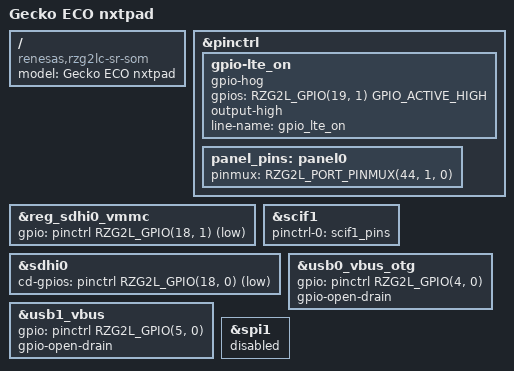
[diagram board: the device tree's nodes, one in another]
// SPDX-License-Identifier: (GPL-2.0-only OR BSD-2-Clause)
/*
 * Device Tree Source for the RZ/G2LC Solidrun SOM
 *
 * Copyright (C) 2021 Renesas Electronics Corp.
 */

#include <dt-bindings/gpio/gpio.h>
#include <dt-bindings/pinctrl/rzg2l-pinctrl.h>

/dts-v1/;
#include "rzg2lc-sr-som.dtsi"
#include "rz-hummingboard-common.dtsi"

/ {
  model = "Gecko ECO nxtpad";
  compatible = "renesas,rzg2lc-sr-som", "renesas,r9a07g044c2", "renesas,r9a07g044";
};

&pinctrl {
	/delete-node/ gpio-lte_reset;
	/delete-node/ spi1;

	gpio-lte_on {
		gpio-hog;
		gpios = <RZG2L_GPIO(19, 1) GPIO_ACTIVE_HIGH>;
		output-high;
		line-name = "gpio_lte_on";
	};

	panel_pins: panel0 {
		pinmux = <RZG2L_PORT_PINMUX(44, 1, 0)>;
	};
};

&reg_sdhi0_vmmc {
	gpio = <&pinctrl RZG2L_GPIO(18, 1) GPIO_ACTIVE_LOW>;
};

&scif1 {
	pinctrl-0 = <&scif1_pins>;
	pinctrl-names = "default";

	//uart-has-rtscts;
	status = "okay";
};

&sdhi0 {
	cd-gpios = <&pinctrl RZG2L_GPIO(18, 0) GPIO_ACTIVE_LOW>;
};

&usb0_vbus_otg {
	gpio = <&pinctrl RZG2L_GPIO(4, 0) GPIO_ACTIVE_HIGH>;
	gpio-open-drain;
};

&usb1_vbus {
	gpio = <&pinctrl RZG2L_GPIO(5, 0) GPIO_ACTIVE_HIGH>;
	gpio-open-drain;
};

&spi1 {
	status = "disabled";
};
